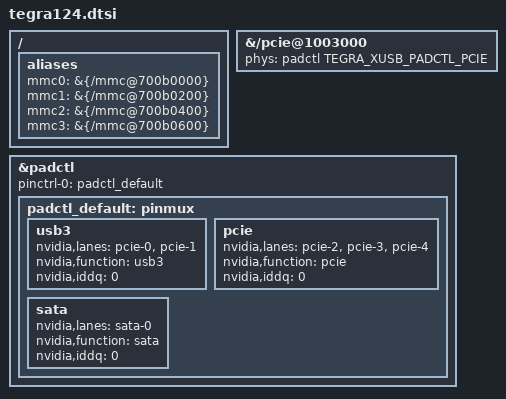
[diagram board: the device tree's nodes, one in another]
#include <dt-bindings/pinctrl/pinctrl-tegra-xusb.h>

/ {
	aliases {
		mmc0 = &{/mmc@700b0000};
		mmc1 = &{/mmc@700b0200};
		mmc2 = &{/mmc@700b0400};
		mmc3 = &{/mmc@700b0600};
	};
};

&{/pcie@1003000} {
	phys = <&padctl TEGRA_XUSB_PADCTL_PCIE>;
	phy-names = "pcie";
};

&padctl {
	pinctrl-0 = <&padctl_default>;
	pinctrl-names = "default";
	#phy-cells = <1>;

	padctl_default: pinmux {
		usb3 {
			nvidia,lanes = "pcie-0", "pcie-1";
			nvidia,function = "usb3";
			nvidia,iddq = <0>;
		};

		pcie {
			nvidia,lanes = "pcie-2", "pcie-3",
				       "pcie-4";
			nvidia,function = "pcie";
			nvidia,iddq = <0>;
		};

		sata {
			nvidia,lanes = "sata-0";
			nvidia,function = "sata";
			nvidia,iddq = <0>;
		};
	};
};
